# ATmega1284P register map
Vendor: Atmel; Series: ATmega128; File version: 1.1
CPU: other r0p0, little endian, no MPU, no FPU, VTOR, 4 interrupt priority bits
Registers are 8-bit, read-write, reset 0x0 unless marked. A register's access mark holds for its fields unless they carry their own. Offsets are from the block's base; [hi:lo] are bit positions.

## FUSE — Fuses
Base 0x00000000
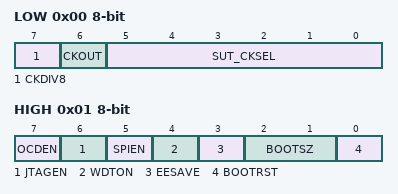
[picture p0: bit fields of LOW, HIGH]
0x00 LOW
  [7] CKDIV8 — Divide clock by 8 internally
  [6] CKOUT — Clock output on PORTB1
  [5:0] SUT_CKSEL — Select Clock Source
    0=EXTCLK_6CK_0MS (Ext. Clock; Start-up time: 6 CK + 0 ms); 2=INTRCOSC_6CK_0MS (Int. RC Osc.; Start-up time: 6 CK + 0 ms); 3=INTRCOSC_128KHZ_6CK_0MS (Int. 128kHz RC Osc.; Start-up time: 6 CK + 0 ms); 4=EXTLOFXTAL_1KCK_0MS (Ext. Low-Freq. Crystal; Start-up time: 1K CK + 0 ms); 5=EXTLOFXTAL_32KCK_0MS (Ext. Low-Freq. Crystal; Start-up time: 32K CK + 0 ms); 6=FSOSC_258CK_4MS1_CRES_FASTPWR (Full Swing Oscillator; Start-up time: 258 CK + 4.1 ms; Ceramic res.; fast rising power); 7=FSOSC_1KCK_65MS_CRES_SLOWPWR (Full Swing Oscillator; Start-up time: 1K CK + 65 ms; Ceramic res.; slowly rising power); 8=EXTXOSC_0MHZ4_0MHZ9_258CK_4MS1 (Ext. Crystal Osc. 0.4-0.9 MHz; Start-up time: 258 CK + 4.1 ms); 9=EXTXOSC_0MHZ4_0MHZ9_1KCK_65MS (Ext. Crystal Osc. 0.4-0.9 MHz; Start-up time: 1K CK + 65 ms); 10=EXTXOSC_0MHZ9_3MHZ_258CK_4MS1 (Ext. Crystal Osc. 0.9-3.0 MHz; Start-up time: 258 CK + 4.1 ms); 11=EXTXOSC_0MHZ9_3MHZ_1KCK_65MS (Ext. Crystal Osc. 0.9-3.0 MHz; Start-up time: 1K CK + 65 ms); 12=EXTXOSC_3MHZ_8MHZ_258CK_4MS1 (Ext. Crystal Osc. 3.0-8.0 MHz; Start-up time: 258 CK + 4.1 ms); 13=EXTXOSC_3MHZ_8MHZ_1KCK_65MS (Ext. Crystal Osc. 3.0-8.0 MHz; Start-up time: 1K CK + 65 ms); 14=EXTXOSC_8MHZ_XX_258CK_4MS1 (Ext. Crystal Osc. 8.0- MHz; Start-up time: 258 CK + 4.1 ms); 15=EXTXOSC_8MHZ_XX_1KCK_65MS (Ext. Crystal Osc. 8.0- MHz; Start-up time: 1K CK + 65 ms); 16=EXTCLK_6CK_4MS1 (Ext. Clock; Start-up time: 6 CK + 4.1 ms); 18=INTRCOSC_6CK_4MS1 (Int. RC Osc.; Start-up time: 6 CK + 4.1 ms); 19=INTRCOSC_128KHZ_6CK_4MS (Int. 128kHz RC Osc.; Start-up time: 6 CK + 4 ms); 20=EXTLOFXTAL_1KCK_4MS1 (Ext. Low-Freq. Crystal; Start-up time: 1K CK + 4.1 ms); 21=EXTLOFXTAL_32KCK_4MS1 (Ext. Low-Freq. Crystal; Start-up time: 32K CK + 4.1 ms); 22=FSOSC_258CK_65MS_CRES_SLOWPWR (Full Swing Oscillator; Start-up time: 258 CK + 65 ms; Ceramic res.; slowly rising power); 23=FSOSC_16KCK_0MS_XOSC_BODEN (Full Swing Oscillator; Start-up time: 16K CK + 0 ms; Crystal Osc.; BOD enabled); 24=EXTXOSC_0MHZ4_0MHZ9_258CK_65MS (Ext. Crystal Osc. 0.4-0.9 MHz; Start-up time: 258 CK + 65 ms); 25=EXTXOSC_0MHZ4_0MHZ9_16KCK_0MS (Ext. Crystal Osc. 0.4-0.9 MHz; Start-up time: 16K CK + 0 ms); 26=EXTXOSC_0MHZ9_3MHZ_258CK_65MS (Ext. Crystal Osc. 0.9-3.0 MHz; Start-up time: 258 CK + 65 ms); 27=EXTXOSC_0MHZ9_3MHZ_16KCK_0MS (Ext. Crystal Osc. 0.9-3.0 MHz; Start-up time: 16K CK + 0 ms); 28=EXTXOSC_3MHZ_8MHZ_258CK_65MS (Ext. Crystal Osc. 3.0-8.0 MHz; Start-up time: 258 CK + 65 ms); 29=EXTXOSC_3MHZ_8MHZ_16KCK_0MS (Ext. Crystal Osc. 3.0-8.0 MHz; Start-up time: 16K CK + 0 ms); 30=EXTXOSC_8MHZ_XX_258CK_65MS (Ext. Crystal Osc. 8.0- MHz; Start-up time: 258 CK + 65 ms); 31=EXTXOSC_8MHZ_XX_16KCK_0MS (Ext. Crystal Osc. 8.0- MHz; Start-up time: 16K CK + 0 ms); 32=EXTCLK_6CK_65MS (Ext. Clock; Start-up time: 6 CK + 65 ms); 34=INTRCOSC_6CK_65MS (Int. RC Osc.; Start-up time: 6 CK + 65 ms); 35=INTRCOSC_128KHZ_6CK_64MS (Int. 128kHz RC Osc.; Start-up time: 6 CK + 64 ms); 36=EXTLOFXTAL_1KCK_65MS (Ext. Low-Freq. Crystal; Start-up time: 1K CK + 65 ms); 37=EXTLOFXTAL_32KCK_65MS (Ext. Low-Freq. Crystal; Start-up time: 32K CK + 65 ms); 38=FSOSC_1KCK_0MS_CRES_BODEN (Full Swing Oscillator; Start-up time: 1K CK + 0 ms; Ceramic res.; BOD enable); 39=FSOSC_16KCK_4MS1_XOSC_FASTPWR (Full Swing Oscillator; Start-up time: 16K CK + 4.1 ms; Crystal Osc.; fast rising power); 40=EXTXOSC_0MHZ4_0MHZ9_1KCK_0MS (Ext. Crystal Osc. 0.4-0.9 MHz; Start-up time: 1K CK + 0 ms); 41=EXTXOSC_0MHZ4_0MHZ9_16KCK_4MS1 (Ext. Crystal Osc. 0.4-0.9 MHz; Start-up time: 16K CK + 4.1 ms); 42=EXTXOSC_0MHZ9_3MHZ_1KCK_0MS (Ext. Crystal Osc. 0.9-3.0 MHz; Start-up time: 1K CK + 0 ms); 43=EXTXOSC_0MHZ9_3MHZ_16KCK_4MS1 (Ext. Crystal Osc. 0.9-3.0 MHz; Start-up time: 16K CK + 4.1 ms); 44=EXTXOSC_3MHZ_8MHZ_1KCK_0MS (Ext. Crystal Osc. 3.0-8.0 MHz; Start-up time: 1K CK + 0 ms); 45=EXTXOSC_3MHZ_8MHZ_16KCK_4MS1 (Ext. Crystal Osc. 3.0-8.0 MHz; Start-up time: 16K CK + 4.1 ms); 46=EXTXOSC_8MHZ_XX_1KCK_0MS (Ext. Crystal Osc. 8.0- MHz; Start-up time: 1K CK + 0 ms); 47=EXTXOSC_8MHZ_XX_16KCK_4MS1 (Ext. Crystal Osc. 8.0- MHz; Start-up time: 16K CK + 4.1 ms); 54=FSOSC_1KCK_4MS1_CRES_FASTPWR (Full Swing Oscillator; Start-up time: 1K CK + 4.1 ms; Ceramic res.; fast rising power); 55=FSOSC_16KCK_65MS_XOSC_SLOWPWR (Full Swing Oscillator; Start-up time: 16K CK + 65 ms; Crystal Osc.; slowly rising power); 56=EXTXOSC_0MHZ4_0MHZ9_1KCK_4MS1 (Ext. Crystal Osc. 0.4-0.9 MHz; Start-up time: 1K CK + 4.1 ms); 57=EXTXOSC_0MHZ4_0MHZ9_16KCK_65MS (Ext. Crystal Osc. 0.4-0.9 MHz; Start-up time: 16K CK + 65 ms); 58=EXTXOSC_0MHZ9_3MHZ_1KCK_4MS1 (Ext. Crystal Osc. 0.9-3.0 MHz; Start-up time: 1K CK + 4.1 ms); 59=EXTXOSC_0MHZ9_3MHZ_16KCK_65MS (Ext. Crystal Osc. 0.9-3.0 MHz; Start-up time: 16K CK + 65 ms); 60=EXTXOSC_3MHZ_8MHZ_1KCK_4MS1 (Ext. Crystal Osc. 3.0-8.0 MHz; Start-up time: 1K CK + 4.1 ms); 61=EXTXOSC_3MHZ_8MHZ_16KCK_65MS (Ext. Crystal Osc. 3.0-8.0 MHz; Start-up time: 16K CK + 65 ms); 62=EXTXOSC_8MHZ_XX_1KCK_4MS1 (Ext. Crystal Osc. 8.0- MHz; Start-up time: 1K CK + 4.1 ms); 63=EXTXOSC_8MHZ_XX_16KCK_65MS (Ext. Crystal Osc. 8.0- MHz; Start-up time: 16K CK + 65 ms)
0x01 HIGH
  [7] OCDEN — On-Chip Debug Enabled
  [6] JTAGEN — JTAG Interface Enabled
  [5] SPIEN — Serial program downloading (SPI) enabled
  [4] WDTON — Watchdog timer always on
  [3] EESAVE — Preserve EEPROM through the Chip Erase cycle
  [2:1] BOOTSZ — Select Boot Size
    0=4096W_F000 (Boot Flash size=4096 words Boot address=$F000); 1=2048W_F800 (Boot Flash size=2048 words Boot address=$F800); 2=1024W_FC00 (Boot Flash size=1024 words Boot address=$FC00); 3=512W_FE00 (Boot Flash size=512 words Boot start address=$FE00)
  [0] BOOTRST — Boot Reset vector Enabled
0x02 EXTENDED
  [2:0] BODLEVEL — Brown-out Detector trigger level
    4=4V3 (Brown-out detection at VCC=4.3 V); 5=2V7 (Brown-out detection at VCC=2.7 V); 6=1V8 (Brown-out detection at VCC=1.8 V); 7=DISABLED (Brown-out detection disabled; [BODLEVEL=111])
